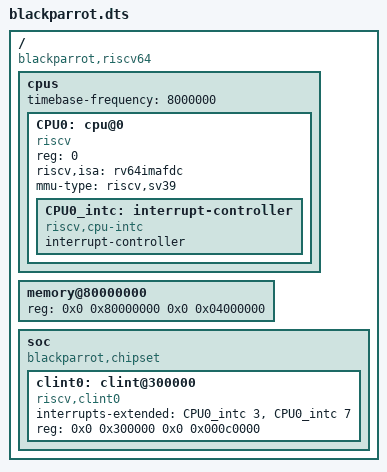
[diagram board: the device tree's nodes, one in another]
/dts-v1/;

/ {
    #address-cells = <2>;
    #size-cells = <2>;
    compatible = "blackparrot,riscv64";

    cpus {
        #address-cells = <1>;
        #size-cells = <0>;
        timebase-frequency = <8000000>;

        CPU0: cpu@0 {
            device_type = "cpu";
            reg = <0>;
            status = "okay";
            compatible = "riscv";
            riscv,isa = "rv64imafdc";
            mmu-type = "riscv,sv39";

            CPU0_intc: interrupt-controller {
                #interrupt-cells = <1>;
                interrupt-controller;
                compatible = "riscv,cpu-intc";
            };
        };
    };

    memory@80000000 {
        device_type = "memory";
        reg = <0x0 0x80000000 0x0 0x04000000>;
    };

    soc {
        #address-cells = <2>;
        #size-cells = <2>;
        compatible = "blackparrot,chipset", "simple-bus";
        ranges;

        clint0: clint@300000 {
            compatible = "riscv,clint0", "blackparrot,clint";
            interrupts-extended = <&CPU0_intc 3 &CPU0_intc 7>;
            reg = <0x0 0x300000 0x0 0x000c0000>;
        };
    };
};
